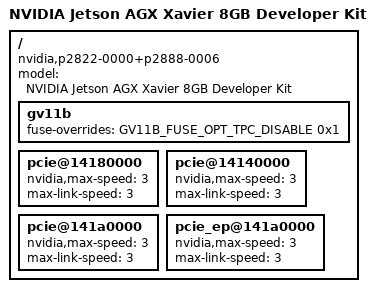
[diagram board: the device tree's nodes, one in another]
/*
 * Copyright (c) 2019-2020, NVIDIA CORPORATION.  All rights reserved.
 *
 * This program is free software; you can redistribute it and/or modify it
 * under the terms and conditions of the GNU General Public License,
 * version 2, as published by the Free Software Foundation.
 *
 * This program is distributed in the hope it will be useful, but WITHOUT
 * ANY WARRANTY; without even the implied warranty of MERCHANTABILITY or
 * FITNESS FOR A PARTICULAR PURPOSE.  See the GNU General Public License for
 * more details.
 *
 * You should have received a copy of the GNU General Public License
 * along with this program.  If not, see <http://www.gnu.org/licenses/>.
 */

/*
 * Top level DTS file for CVM:P2888-0006 and CVB:P2822-0000.
 */

#include "common/tegra194-p2888-0001-p2822-0000-common.dtsi"
#include "common/tegra194-p2822-camera-modules.dtsi"
#include "t19x-common-modules/tegra194-camera-plugin-manager.dtsi"
#include "dt-bindings/soc/gv11b-fuse.h"
#include "common/tegra194-p2888-0006-p2822-common.dtsi"
#include "common/tegra194-audio-p2822-0000.dtsi"

/ {
	model = "NVIDIA Jetson AGX Xavier 8GB Developer Kit";
	compatible = "nvidia,p2822-0000+p2888-0006", "nvidia,p2972-0006", "nvidia,tegra194";

	gv11b {
		fuse-overrides = <GV11B_FUSE_OPT_TPC_DISABLE 0x1>;
	};

	pcie@14180000 {
		nvidia,max-speed = <3>;
		max-link-speed = <3>;
	};

	pcie@14140000 {
		nvidia,max-speed = <3>;
		max-link-speed = <3>;
	};

	pcie@141a0000 {
		nvidia,max-speed = <3>;
		max-link-speed = <3>;
	};

	pcie_ep@141a0000 {
		nvidia,max-speed = <3>;
		max-link-speed = <3>;
	};
};
